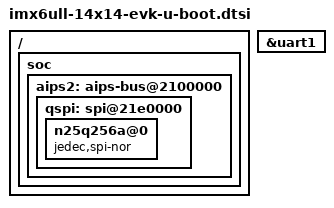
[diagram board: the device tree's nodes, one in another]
// SPDX-License-Identifier: GPL-2.0+
/*
 * Copyright 2018 NXP
 */

&uart1 {
	u-boot,dm-spl;
};

/ {
	soc {
		u-boot,dm-spl;

		aips2: aips-bus@2100000 {
			u-boot,dm-spl;

			qspi: spi@21e0000 {
				u-boot,dm-spl;

				n25q256a@0 {
					/*
					 * Necessary for high speed QSPI
					 * reading in U-Boot:
					 * Without:	5.7 MiB/s
					 * With:	20 MiB/s
					 */
					compatible = "jedec,spi-nor";
				};
			};
		};
	};
};
